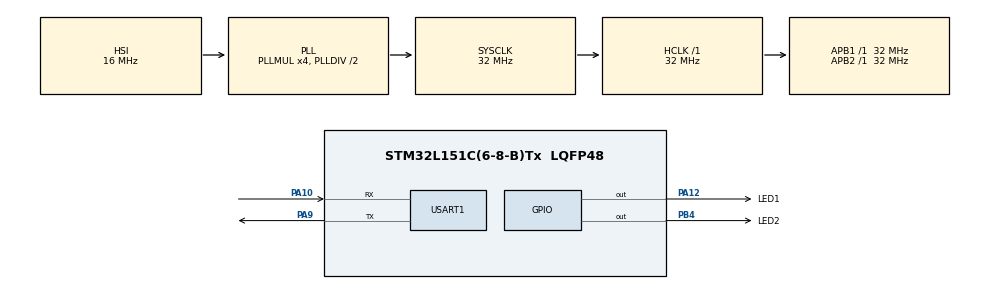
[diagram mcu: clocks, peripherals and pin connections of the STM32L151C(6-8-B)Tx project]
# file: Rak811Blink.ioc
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Mcu.Family=STM32L1
Mcu.Name=STM32L151C(6-8-B)Tx
Mcu.Package=LQFP48
NVIC.PriorityGroup=NVIC_PRIORITYGROUP_4
PA10.Mode=Asynchronous
PA10.Signal=USART1_RX
PA12.GPIO_Label=LED1
PA12.PinState=GPIO_PIN_SET
PA12.Signal=GPIO_Output
PA13.Mode=Serial_Wire
PA13.Signal=SYS_JTMS-SWDIO
PA14.Mode=Serial_Wire
PA14.Signal=SYS_JTCK-SWCLK
PA9.Mode=Asynchronous
PA9.Signal=USART1_TX
PB4.GPIO_Label=LED2
PB4.GPIO_Speed=GPIO_SPEED_FREQ_LOW
PB4.PinState=GPIO_PIN_SET
PB4.Signal=GPIO_Output
PH0-OSC_IN.Mode=HSE-External-Oscillator
PH0-OSC_IN.Signal=RCC_OSC_IN
PH1-OSC_OUT.Mode=HSE-External-Oscillator
PH1-OSC_OUT.Signal=RCC_OSC_OUT
ProjectManager.HeapSize=0x200
ProjectManager.StackSize=0x400
ProjectManager.TargetToolchain=SW4STM32
RCC.48MHZClocksFreq_Value=32000000
RCC.AHBFreq_Value=32000000
RCC.APB1Freq_Value=32000000
RCC.APB1TimFreq_Value=32000000
RCC.APB2Freq_Value=32000000
RCC.APB2TimFreq_Value=32000000
RCC.HCLKFreq_Value=32000000
RCC.HSE_VALUE=24000000
RCC.HSI_VALUE=16000000
RCC.LSE_VALUE=32768
RCC.MSI_VALUE=2097000
RCC.PLLMUL=RCC_PLL_MUL4
RCC.SYSCLKFreq_VALUE=32000000
RCC.SYSCLKSource=RCC_SYSCLKSOURCE_PLLCLK
RCC.VCOOutputFreq_Value=64000000
USART1.VirtualMode=VM_ASYNC
board=custom

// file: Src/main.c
/**
  ******************************************************************************
  * @file           : main.c
  * @brief          : Main program body
  ******************************************************************************
  ** This notice applies to any and all portions of this file
  * that are not between comment pairs USER CODE BEGIN and
  * USER CODE END. Other portions of this file, whether
  * inserted by the user or by software development tools
  * are owned by their respective copyright owners.
  *
  * COPYRIGHT(c) 2018 STMicroelectronics
  *
  * Redistribution and use in source and binary forms, with or without modification,
  * are permitted provided that the following conditions are met:
  *   1. Redistributions of source code must retain the above copyright notice,
  *      this list of conditions and the following disclaimer.
  *   2. Redistributions in binary form must reproduce the above copyright notice,
  *      this list of conditions and the following disclaimer in the documentation
  *      and/or other materials provided with the distribution.
  *   3. Neither the name of STMicroelectronics nor the names of its contributors
  *      may be used to endorse or promote products derived from this software
  *      without specific prior written permission.
  *
  * THIS SOFTWARE IS PROVIDED BY THE COPYRIGHT HOLDERS AND CONTRIBUTORS "AS IS"
  * AND ANY EXPRESS OR IMPLIED WARRANTIES, INCLUDING, BUT NOT LIMITED TO, THE
  * IMPLIED WARRANTIES OF MERCHANTABILITY AND FITNESS FOR A PARTICULAR PURPOSE ARE
  * DISCLAIMED. IN NO EVENT SHALL THE COPYRIGHT HOLDER OR CONTRIBUTORS BE LIABLE
  * FOR ANY DIRECT, INDIRECT, INCIDENTAL, SPECIAL, EXEMPLARY, OR CONSEQUENTIAL
  * DAMAGES (INCLUDING, BUT NOT LIMITED TO, PROCUREMENT OF SUBSTITUTE GOODS OR
  * SERVICES; LOSS OF USE, DATA, OR PROFITS; OR BUSINESS INTERRUPTION) HOWEVER
  * CAUSED AND ON ANY THEORY OF LIABILITY, WHETHER IN CONTRACT, STRICT LIABILITY,
  * OR TORT (INCLUDING NEGLIGENCE OR OTHERWISE) ARISING IN ANY WAY OUT OF THE USE
  * OF THIS SOFTWARE, EVEN IF ADVISED OF THE POSSIBILITY OF SUCH DAMAGE.
  *
  ******************************************************************************
  */
#include "main.h"
#include "stm32l1xx_hal.h"

UART_HandleTypeDef huart1;

/* USER CODE BEGIN PV */
/* Private variables ---------------------------------------------------------*/

/* USER CODE END PV */

void SystemClock_Config(void);
static void MX_GPIO_Init(void);
static void MX_USART1_UART_Init(void);

/* USER CODE BEGIN PFP */
/* Private function prototypes -----------------------------------------------*/

/* USER CODE END PFP */

int main(void)
{
  /* USER CODE BEGIN 1 */
	uint8_t ledCnt =0;
	GPIO_PinState ledState;

  /* USER CODE END 1 */

  /* MCU Configuration----------------------------------------------------------*/

  /* Reset of all peripherals, Initializes the Flash interface and the Systick. */
  HAL_Init();

  /* Configure the system clock */
  SystemClock_Config();

  /* Initialize all configured peripherals */
  MX_GPIO_Init();
  MX_USART1_UART_Init();
  /* USER CODE BEGIN 2 */
  printf("Make the two LEDs on the Rak811 tracker board blink\r\n");
  /* USER CODE END 2 */

  /* Infinite loop */
  /* USER CODE BEGIN WHILE */
  while (1)
  {
	  HAL_Delay(1000);
	  ledState = (ledCnt & 1) ? GPIO_PIN_RESET: GPIO_PIN_SET;
	  HAL_GPIO_WritePin(LED1_GPIO_Port, LED1_Pin,ledState);
	  ledState = (ledCnt & 2) ? GPIO_PIN_RESET: GPIO_PIN_SET;
	  HAL_GPIO_WritePin(LED2_GPIO_Port, LED2_Pin,ledState);
	  ledCnt ++;
	  if (ledCnt > 3)
		  ledCnt = 0;

  /* USER CODE END WHILE */

  }

}

void SystemClock_Config(void)
{

  RCC_OscInitTypeDef RCC_OscInitStruct;
  RCC_ClkInitTypeDef RCC_ClkInitStruct;

    /**Configure the main internal regulator output voltage
    */
  __HAL_PWR_VOLTAGESCALING_CONFIG(PWR_REGULATOR_VOLTAGE_SCALE1);

    /**Initializes the CPU, AHB and APB busses clocks
    */
  RCC_OscInitStruct.OscillatorType = RCC_OSCILLATORTYPE_HSI;
  RCC_OscInitStruct.HSIState = RCC_HSI_ON;
  RCC_OscInitStruct.HSICalibrationValue = 16;
  RCC_OscInitStruct.PLL.PLLState = RCC_PLL_ON;
  RCC_OscInitStruct.PLL.PLLSource = RCC_PLLSOURCE_HSI;
  RCC_OscInitStruct.PLL.PLLMUL = RCC_PLL_MUL4;
  RCC_OscInitStruct.PLL.PLLDIV = RCC_PLL_DIV2;
  if (HAL_RCC_OscConfig(&RCC_OscInitStruct) != HAL_OK)
  {
    _Error_Handler(__FILE__, __LINE__);
  }

    /**Initializes the CPU, AHB and APB busses clocks
    */
  RCC_ClkInitStruct.ClockType = RCC_CLOCKTYPE_HCLK|RCC_CLOCKTYPE_SYSCLK
                              |RCC_CLOCKTYPE_PCLK1|RCC_CLOCKTYPE_PCLK2;
  RCC_ClkInitStruct.SYSCLKSource = RCC_SYSCLKSOURCE_PLLCLK;
  RCC_ClkInitStruct.AHBCLKDivider = RCC_SYSCLK_DIV1;
  RCC_ClkInitStruct.APB1CLKDivider = RCC_HCLK_DIV1;
  RCC_ClkInitStruct.APB2CLKDivider = RCC_HCLK_DIV1;

  if (HAL_RCC_ClockConfig(&RCC_ClkInitStruct, FLASH_LATENCY_1) != HAL_OK)
  {
    _Error_Handler(__FILE__, __LINE__);
  }

    /**Configure the Systick interrupt time
    */
  HAL_SYSTICK_Config(HAL_RCC_GetHCLKFreq()/1000);

    /**Configure the Systick
    */
  HAL_SYSTICK_CLKSourceConfig(SYSTICK_CLKSOURCE_HCLK);

  /* SysTick_IRQn interrupt configuration */
  HAL_NVIC_SetPriority(SysTick_IRQn, 0, 0);
}

/* USART1 init function */
static void MX_USART1_UART_Init(void)
{

  huart1.Instance = USART1;
  huart1.Init.BaudRate = 115200;
  huart1.Init.WordLength = UART_WORDLENGTH_8B;
  huart1.Init.StopBits = UART_STOPBITS_1;
  huart1.Init.Parity = UART_PARITY_NONE;
  huart1.Init.Mode = UART_MODE_TX_RX;
  huart1.Init.HwFlowCtl = UART_HWCONTROL_NONE;
  huart1.Init.OverSampling = UART_OVERSAMPLING_16;
  if (HAL_UART_Init(&huart1) != HAL_OK)
  {
    _Error_Handler(__FILE__, __LINE__);
  }

}

/** Configure pins as
        * Analog
        * Input
        * Output
        * EVENT_OUT
        * EXTI
*/
static void MX_GPIO_Init(void)
{

  GPIO_InitTypeDef GPIO_InitStruct;

  /* GPIO Ports Clock Enable */
  __HAL_RCC_GPIOH_CLK_ENABLE();
  __HAL_RCC_GPIOA_CLK_ENABLE();
  __HAL_RCC_GPIOB_CLK_ENABLE();

  /*Configure GPIO pin Output Level */
  HAL_GPIO_WritePin(LED1_GPIO_Port, LED1_Pin, GPIO_PIN_SET);

  /*Configure GPIO pin Output Level */
  HAL_GPIO_WritePin(LED2_GPIO_Port, LED2_Pin, GPIO_PIN_SET);

  /*Configure GPIO pin : LED1_Pin */
  GPIO_InitStruct.Pin = LED1_Pin;
  GPIO_InitStruct.Mode = GPIO_MODE_OUTPUT_PP;
  GPIO_InitStruct.Pull = GPIO_NOPULL;
  GPIO_InitStruct.Speed = GPIO_SPEED_FREQ_LOW;
  HAL_GPIO_Init(LED1_GPIO_Port, &GPIO_InitStruct);

  /*Configure GPIO pin : LED2_Pin */
  GPIO_InitStruct.Pin = LED2_Pin;
  GPIO_InitStruct.Mode = GPIO_MODE_OUTPUT_PP;
  GPIO_InitStruct.Pull = GPIO_NOPULL;
  GPIO_InitStruct.Speed = GPIO_SPEED_FREQ_LOW;
  HAL_GPIO_Init(LED2_GPIO_Port, &GPIO_InitStruct);

}

void _Error_Handler(char *file, int line)
{
  while(1)
  {
  }
}

/************************ (C) COPYRIGHT STMicroelectronics *****END OF FILE****/
